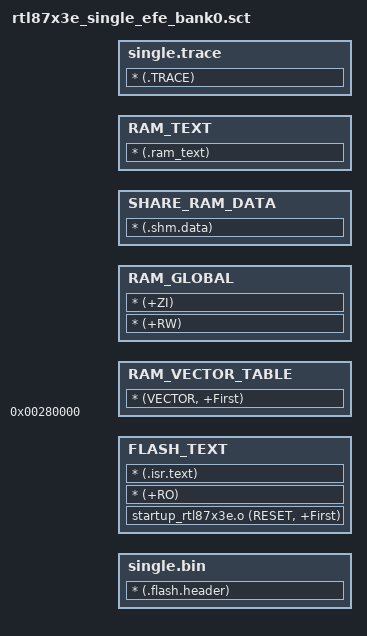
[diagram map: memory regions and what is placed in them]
#! armcc -E
#include "..\..\inc\rtl87x3e_efe\mem_config.h"
#include "..\..\..\..\..\bin\rtl87x3e\flash_map_config\flash_map.h"

; *************************************************************
; *** Scatter-Loading Description File generated by uVision ***
; *************************************************************

; Build Bank Configure
#define BUILD_BANK              0   //Bank0 as default

; Enable RAM Code
#define FEATURE_RAM_CODE        0

; Use Cache RAM to run RAM Code
#define FEATURE_CACHE_RAM_CODE  0

; APP RAM definitions
;#define DATA_RAM_ON_ADR     DATA_RAM_START_ADDR
;#define BUFFER_RAM_ON_ADR   BUFFER_RAM_START_ADDR

#define RAM_GLOBAL_ADDR     APP_GLOBAL_ADDR
#define RAM_GLOBAL_SIZE     APP_GLOBAL_SIZE

#define APP_BUFFER_ON_ADR   APP_RAM_TEXT_ADDR
#define APP_BUFFER_ON_SIZE  APP_RAM_TEXT_SIZE

#define DSP_SHARE_RAM_TEXT_ADDR     DSP_SHM_GLOBAL_ADDR
#define DSP_SHARE_RAM_TEXT_SIZE     DSP_SHM_GLOBAL_SIZE

; APP Flash definitions
#if !BUILD_BANK
#define APP_FLASH_ADR       BANK0_APP_ADDR
#define APP_FLASH_SIZE      BANK0_APP_SIZE
#else
#define APP_FLASH_ADR       BANK1_APP_ADDR
#define APP_FLASH_SIZE      BANK1_APP_SIZE
#endif

;#define APP_TRACE_ADR       0x08800000
;#define APP_TRACE_SIZE      (4*1024*1024)

;#define RAM_CACHE_ADR       (BUFFER_RAM_ON_ADR+64*1024+240*1024)
;#define RAM_CACHE_SIZE      (16*1024)

LOAD_FLASH APP_FLASH_ADR APP_FLASH_SIZE
{
    single.bin +0
    {
        * (.flash.header)
    }

    FLASH_TEXT +0;
    {
        startup_rtl87x3e.o (RESET, +First)
#if (FEATURE_RAM_CODE == 0)
        * (+RO)
#endif
        * (.isr.text)
    }

    RAM_VECTOR_TABLE 0x280000
    {
        * (VECTOR, +First)
    }

    RAM_GLOBAL RAM_GLOBAL_ADDR RAM_GLOBAL_SIZE
    {
        * (+RW)
        * (+ZI)
    }

    SHARE_RAM_DATA DSP_SHARE_RAM_TEXT_ADDR DSP_SHARE_RAM_TEXT_SIZE
    {
        * (.shm.data)
    }

    RAM_TEXT APP_BUFFER_ON_ADR APP_BUFFER_ON_SIZE
    {
#if FEATURE_RAM_CODE
        .ANY (+RO)
#endif
        * (.ram_text)
    }

}

LOAD_APP_TRACE APP_TRACE_ADR APP_TRACE_SIZE
{
    single.trace APP_TRACE_ADR APP_TRACE_SIZE
    {
        * (.TRACE)
    }
}

